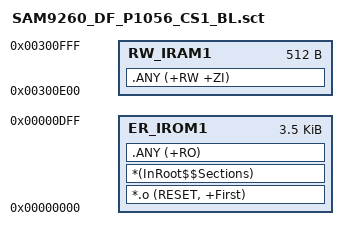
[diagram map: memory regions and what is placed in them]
; *************************************************************
; *** Scatter-Loading Description File generated by uVision ***
; *************************************************************

LR_IROM1 0x00000000 0x00000E00  {    ; load region size_region
  ER_IROM1 0x00000000 0x00000E00  {  ; load address = execution address
   *.o (RESET, +First)
   *(InRoot$$Sections)
   .ANY (+RO)
  }
  RW_IRAM1 0x00300E00 0x00000200  {  ; RW data
   .ANY (+RW +ZI)
  }
}

